# R7FA4L1BD register map
Vendor: Renesas Electronics Corporation; Series: RA4; File version: 0.90.02
CPU: CM33 r0p4, little endian, MPU, FPU, VTOR, 4 interrupt priority bits, 96 interrupts
Registers are 32-bit, read-write, reset 0x0 unless marked. A register's access mark holds for its fields unless they carry their own. Offsets are from the block's base; [hi:lo] are bit positions.

## PSCU — Peripheral Security Control Unit
Base 0x400E0000
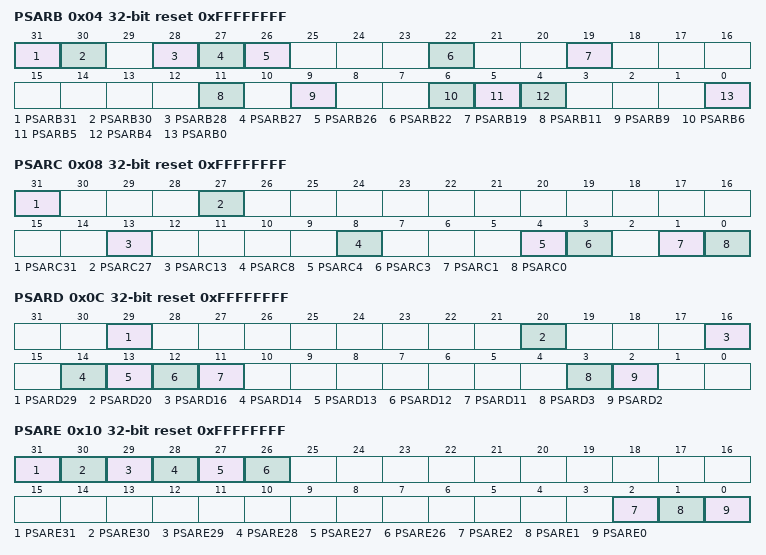
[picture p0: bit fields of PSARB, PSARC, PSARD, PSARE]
0x04 PSARB reset 0xFFFFFFFF — Peripheral Security Attribution Register B
  [31] PSARB31 — SCI0 and the MSTPCRB.MSTPB31 Bit Security Attribution
    0=Secure; 1=Non-secure
  [30] PSARB30 — SCI1 and the MSTPCRB.MSTPB30 Bit Security Attribution
    0=Secure; 1=Non-secure
  [28] PSARB28 — SCI3 and the MSTPCRB.MSTPB28 Bit Security Attribution
    0=Secure; 1=Non-secure
  [27] PSARB27 — SCI4 and the MSTPCRB.MSTPB27 Bit Security Attribution
    0=Secure; 1=Non-secure
  [26] PSARB26 — SCI5 and the MSTPCRB.MSTPB26 Bit Security Attribution
    0=Secure; 1=Non-secure
  [22] PSARB22 — SCI9 and the MSTPCRB.MSTPB22 Bit Security Attribution
    0=Secure; 1=Non-secure
  [19] PSARB19 — SPI0 and the MSTPCRB.MSTPB19 Bit Security Attribution
    0=Secure; 1=Non-secure
  [11] PSARB11 — USBFS and the MSTPCRB.MSTPB11 Bit Security Attribution
    0=Secure; 1=Non-secure
  [9] PSARB9 — IIC0 and the MSTPCRB.MSTPB9 Bit Security Attribution
    0=Secure; 1=Non-secure
  [6] PSARB6 ro — QSPI and the MSTPCRB.MSTPB6 Bit Security Attribution
  [5] PSARB5 — IrDA and the MSTPCRB.MSTPB5 Bit Security Attribution
    0=Secure; 1=Non-secure
  [4] PSARB4 — I3C and the MSTPCRB.MSTPB4 Bit Security Attribution
    0=Secure; 1=Non-secure
  [0] PSARB0 — UARTA and the MSTPCRB.MSTPB0 Bit Security Attribution
    0=Secure; 1=Non-secure
0x08 PSARC reset 0xFFFFFFFF — Peripheral Security Attribution Register C
  [all] fields
    0=Secure; 1=Non-secure
  [31] PSARC31 — RSIP-E11A and the MSTPCRC.MSTPC31 Bit Security Attribution
  [27] PSARC27 — CANFD0 and the MSTPCRC.MSTPC27 Bit Security Attribution
  [13] PSARC13 — DOC and the MSTPCRC.MSTPC13 Bit Security Attribution
  [8] PSARC8 — SSIE0 and the MSTPCRC.MSTPC8 Bit Security Attribution
  [4] PSARC4 — SLCDC and the MSTPCRB.MSTPC4 Bit Security Attribution
  [3] PSARC3 — CTSU and the MSTPCRC.MSTPC3 Bit Security Attribution
  [1] PSARC1 — CRC and the MSTPCRC.MSTPC1 Bit Security Attribution
  [0] PSARC0 — CAC and the MSTPCRC.MSTPC0 Bit Security Attribution
0x0C PSARD reset 0xFFFFFFFF — Peripheral Security Attribution Register D
  [all] fields
    0=Secure; 1=Non-secure
  [29] PSARD29 — ACMPLP and the MSTPCRD.MSTPD29 Bit Security Attribution
  [20] PSARD20 — DAC12 and the MSTPCRD.MSTPD20 Bit Security Attribution
  [16] PSARD16 — ADC120 and the MSTPCRD.MSTPD16 Bit Security Attribution
  [14] PSARD14 — POEG Group A and the MSTPCRD.MSTPD14 Bit Security Attribution
  [13] PSARD13 — POEG Group B and the MSTPCRD.MSTPD13 Bit Security Attribution
  [12] PSARD12 — POEG Group C and the MSTPCRD.MSTPD12 Bit Security Attribution
  [11] PSARD11 — POEG Group D and the MSTPCRD.MSTPD11 Bit Security Attribution
  [3] PSARD3 — AGT0 and the MSTPCRD.MSTPD3 Bit Security Attribution
  [2] PSARD2 — AGT1 and the MSTPCRD.MSTPD2 Bit Security Attribution
0x10 PSARE reset 0xFFFFFFFF — Peripheral Security Attribution Register E
  [all] fields
    0=Secure; 1=Non-secure
  [31] PSARE31 — GPT0, GPT_OPS and the MSTPCRE.MSTPE31 Bit Security Attribution
  [30] PSARE30 — GPT1 and the MSTPCRE.MSTPE30 Bit Security Attribution
  [29] PSARE29 — GPT2 and the MSTPCRE.MSTPE29 Bit Security Attribution
  [28] PSARE28 — GPT3 and the MSTPCRE.MSTPE28 Bit Security Attribution
  [27] PSARE27 — GPT4 and the MSTPCRE.MSTPE27 Bit Security Attribution
  [26] PSARE26 — GPT5 and the MSTPCRE.MSTPE26 Bit Security Attribution
  [2] PSARE2 — RTC Security Attribution
  [1] PSARE1 — IWDT Security Attribution
  [0] PSARE0 — WDT Security Attribution
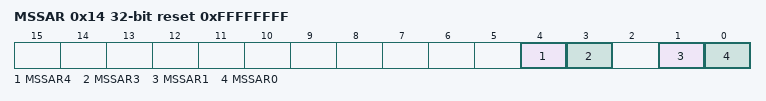
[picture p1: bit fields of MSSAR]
0x14 MSSAR reset 0xFFFFFFFF — Module Stop Security Attribution Register
  [all] fields
    0=Secure; 1=Non-secure
  [4] MSSAR4 — The MSTPCRA.MSMSTPA16 Bit Security Attribution
  [3] MSSAR3 — The MSTPCRA.MSTPA0 Bit Security Attribution
  [1] MSSAR1 — The MSTPCRA.MSTPA22 Bit Security Attribution
  [0] MSSAR0 — The MSTPCRC.MSTPC14 Bit Security Attribution
0x18 CFSAMONA ro (reset mask 0xFF007FFF) — Code Flash Security Attribution Monitor Register A
  [23:15] CFS2 — Code Flash Secure area 2
0x1C CFSAMONB ro (reset mask 0xFF0003FF) — Code Flash Security Attribution Monitor Register B
  [23:10] CFS1 — Code Flash Secure area 1
0x20 DFSAMON ro (reset mask 0xFFFF03FF) — Data Flash Security Attribution Monitor Register
  [15:10] DFS — Data flash Secure area
0x24 SSAMONA ro (reset mask 0xFFE01FFF) — SRAM Security Attribution Monitor Register A
  [20:13] SS2 — SRAM Secure area 2
0x28 SSAMONB ro (reset mask 0xFFE003FF) — SRAM Security Attribution Monitor Register B
  [20:10] SS1 — SRAM secure area 1
0x2C DLMMON ro (reset mask 0xFFFFFFF0) — Device Lifecycle Management State Monitor Register
  [3:0] DLMMON — Device Lifecycle Management State Monitor
    2=SSD; 3=NSECSD; 4=DPL; 5=LCK_DBG; 6=LCK_BOOT; 7=RMA_REQ; 8=RMA_ACK; other=Others (Reserved)
